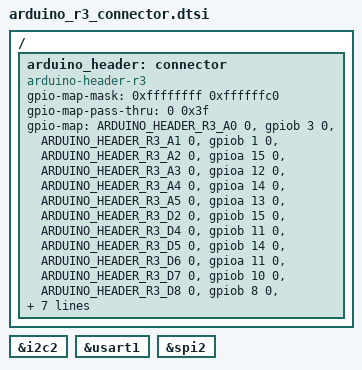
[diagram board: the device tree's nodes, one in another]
/*
 * Copyright (c) 2025 STMicroelectronics
 *
 * SPDX-License-Identifier: Apache-2.0
 */

#include <zephyr/dt-bindings/gpio/arduino-header-r3.h>

/ {
	arduino_header: connector {
		compatible = "arduino-header-r3";
		#gpio-cells = <2>;
		gpio-map-mask = <0xffffffff 0xffffffc0>;
		gpio-map-pass-thru = <0 0x3f>;

		/* Some pins are not connected to the Arduino
		 * connector in default hardware configuration.
		 * Only the connected pins are provided here.
		 */
		gpio-map = <ARDUINO_HEADER_R3_A0 0 &gpiob 3 0>,
			   <ARDUINO_HEADER_R3_A1 0 &gpiob 1 0>,
			   <ARDUINO_HEADER_R3_A2 0 &gpioa 15 0>,
			   <ARDUINO_HEADER_R3_A3 0 &gpioa 12 0>,
			   <ARDUINO_HEADER_R3_A4 0 &gpioa 14 0>,
			   <ARDUINO_HEADER_R3_A5 0 &gpioa 13 0>,
			   /* D0 - N/C (PA8 via SB9) */
			   /* D1 - N/C (PA9 via SB7) */
			   <ARDUINO_HEADER_R3_D2 0 &gpiob 15 0>,
			   /* D3 - N/C (PA0 via SB3) */
			   <ARDUINO_HEADER_R3_D4 0 &gpiob 11 0>,
			   <ARDUINO_HEADER_R3_D5 0 &gpiob 14 0>,
			   <ARDUINO_HEADER_R3_D6 0 &gpioa 11 0>,
			   <ARDUINO_HEADER_R3_D7 0 &gpiob 10 0>,
			   <ARDUINO_HEADER_R3_D8 0 &gpiob 8 0>,
			   <ARDUINO_HEADER_R3_D9 0 &gpioa 1 0>,
			   <ARDUINO_HEADER_R3_D10 0 &gpioa 4 0>,
			   <ARDUINO_HEADER_R3_D11 0 &gpioa 6 0>,
			   <ARDUINO_HEADER_R3_D12 0 &gpioa 7 0>,
			   <ARDUINO_HEADER_R3_D13 0 &gpioa 5 0>,
			   <ARDUINO_HEADER_R3_D14 0 &gpiob 7 0>,
			   <ARDUINO_HEADER_R3_D15 0 &gpiob 6 0>;
	};
};

arduino_i2c: &i2c2 {};

arduino_serial: &usart1 {};

arduino_spi: &spi2 {};
